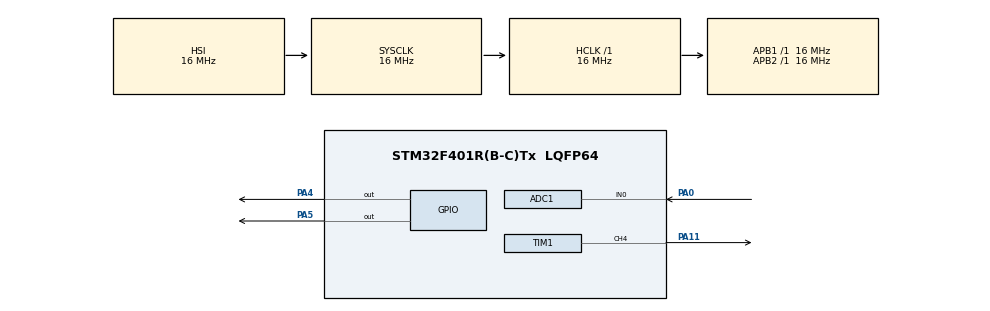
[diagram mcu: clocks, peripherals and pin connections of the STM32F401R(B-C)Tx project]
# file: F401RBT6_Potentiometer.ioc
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ADC1.Channel-2\#ChannelRegularConversion=ADC_CHANNEL_0
ADC1.NbrOfConversionFlag=1
ADC1.Rank-2\#ChannelRegularConversion=1
ADC1.SamplingTime-2\#ChannelRegularConversion=ADC_SAMPLETIME_15CYCLES
ADC1.master=1
Mcu.Family=STM32F4
Mcu.Name=STM32F401R(B-C)Tx
Mcu.Package=LQFP64
NVIC.PriorityGroup=NVIC_PRIORITYGROUP_4
PA0-WKUP.Signal=ADCx_IN0
PA11.Signal=S_TIM1_CH4
PA13.Mode=Serial_Wire
PA13.Signal=SYS_JTMS-SWDIO
PA14.Mode=Serial_Wire
PA14.Signal=SYS_JTCK-SWCLK
PA4.Signal=GPIO_Output
PA5.Signal=GPIO_Output
PC14-OSC32_IN.Mode=LSE-External-Oscillator
PC14-OSC32_IN.Signal=RCC_OSC32_IN
PC15-OSC32_OUT.Mode=LSE-External-Oscillator
PC15-OSC32_OUT.Signal=RCC_OSC32_OUT
PH0\ -\ OSC_IN.Mode=HSE-External-Oscillator
PH0\ -\ OSC_IN.Signal=RCC_OSC_IN
PH1\ -\ OSC_OUT.Mode=HSE-External-Oscillator
PH1\ -\ OSC_OUT.Signal=RCC_OSC_OUT
ProjectManager.HeapSize=0x200
ProjectManager.StackSize=0x400
ProjectManager.TargetToolchain=STM32CubeIDE
RCC.AHBFreq_Value=16000000
RCC.APB1Freq_Value=16000000
RCC.APB2Freq_Value=16000000
RCC.CortexFreq_Value=16000000
RCC.HSE_VALUE=25000000
RCC.HSI_VALUE=16000000
RCC.SYSCLKFreq_VALUE=16000000
RCC.VCOOutputFreq_Value=192000000
SH.ADCx_IN0.0=ADC1_IN0,IN0
SH.S_TIM1_CH4.0=TIM1_CH4,PWM Generation4 CH4
TIM1.AutoReloadPreload=TIM_AUTORELOAD_PRELOAD_ENABLE
TIM1.Channel-PWM\ Generation4\ CH4=TIM_CHANNEL_4
TIM1.Period=999
TIM1.Prescaler=79
board=custom

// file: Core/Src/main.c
/* USER CODE BEGIN Header */
/**
 ******************************************************************************
 * @file           : main.c
 * @brief          : Main program body
 ******************************************************************************
 * @attention
 *
 * Copyright (c) 2025 STMicroelectronics.
 * All rights reserved.
 *
 * This software is licensed under terms that can be found in the LICENSE file
 * in the root directory of this software component.
 * If no LICENSE file comes with this software, it is provided AS-IS.
 *
 ******************************************************************************
 */
/* USER CODE END Header */
#include "main.h"

ADC_HandleTypeDef hadc1;

TIM_HandleTypeDef htim1;

void SystemClock_Config(void);
static void MX_GPIO_Init(void);
static void MX_ADC1_Init(void);
static void MX_TIM1_Init(void);
/* USER CODE BEGIN PFP */
uint32_t adcValue;
uint32_t pwmValue;
/* USER CODE END PFP */

int main(void) {

	/* MCU Configuration--------------------------------------------------------*/

	/* Reset of all peripherals, Initializes the Flash interface and the Systick. */
	HAL_Init();

	/* Configure the system clock */
	SystemClock_Config();

	/* Initialize all configured peripherals */
	MX_GPIO_Init();
	MX_ADC1_Init();
	MX_TIM1_Init();
	/* USER CODE BEGIN 2 */
	HAL_TIM_PWM_Start(&htim1, TIM_CHANNEL_4);
	/* USER CODE END 2 */
	HAL_GPIO_WritePin(GPIOA, GPIO_PIN_4, GPIO_PIN_SET);   // IN1 = HIGH
	HAL_GPIO_WritePin(GPIOA, GPIO_PIN_5, GPIO_PIN_RESET); // IN2 = LOW
	/* Infinite loop */
	while (1) {
		HAL_ADC_Start(&hadc1);
		HAL_ADC_PollForConversion(&hadc1, HAL_MAX_DELAY);
		adcValue = HAL_ADC_GetValue(&hadc1); // 12-bit: 0–4095

		// Map 0–4095 to 0–999 (PWM duty)
		pwmValue = (adcValue * 999) / 4095;

		// Update PWM duty cycle
		__HAL_TIM_SET_COMPARE(&htim1, TIM_CHANNEL_4, pwmValue);

		HAL_Delay(10);
	}
}

void SystemClock_Config(void) {
	RCC_OscInitTypeDef RCC_OscInitStruct = { 0 };
	RCC_ClkInitTypeDef RCC_ClkInitStruct = { 0 };

	/** Configure the main internal regulator output voltage
	 */
	__HAL_RCC_PWR_CLK_ENABLE();
	__HAL_PWR_VOLTAGESCALING_CONFIG(PWR_REGULATOR_VOLTAGE_SCALE2);

	/** Initializes the RCC Oscillators according to the specified parameters
	 * in the RCC_OscInitTypeDef structure.
	 */
	RCC_OscInitStruct.OscillatorType = RCC_OSCILLATORTYPE_HSI;
	RCC_OscInitStruct.HSIState = RCC_HSI_ON;
	RCC_OscInitStruct.HSICalibrationValue = RCC_HSICALIBRATION_DEFAULT;
	RCC_OscInitStruct.PLL.PLLState = RCC_PLL_NONE;
	if (HAL_RCC_OscConfig(&RCC_OscInitStruct) != HAL_OK) {
		Error_Handler();
	}

	/** Initializes the CPU, AHB and APB buses clocks
	 */
	RCC_ClkInitStruct.ClockType = RCC_CLOCKTYPE_HCLK | RCC_CLOCKTYPE_SYSCLK
			| RCC_CLOCKTYPE_PCLK1 | RCC_CLOCKTYPE_PCLK2;
	RCC_ClkInitStruct.SYSCLKSource = RCC_SYSCLKSOURCE_HSI;
	RCC_ClkInitStruct.AHBCLKDivider = RCC_SYSCLK_DIV1;
	RCC_ClkInitStruct.APB1CLKDivider = RCC_HCLK_DIV1;
	RCC_ClkInitStruct.APB2CLKDivider = RCC_HCLK_DIV1;

	if (HAL_RCC_ClockConfig(&RCC_ClkInitStruct, FLASH_LATENCY_0) != HAL_OK) {
		Error_Handler();
	}
}

static void MX_ADC1_Init(void) {

	ADC_ChannelConfTypeDef sConfig = { 0 };

	/** Configure the global features of the ADC (Clock, Resolution, Data Alignment and number of conversion)
	 */
	hadc1.Instance = ADC1;
	hadc1.Init.ClockPrescaler = ADC_CLOCK_SYNC_PCLK_DIV2;
	hadc1.Init.Resolution = ADC_RESOLUTION_12B;
	hadc1.Init.ScanConvMode = DISABLE;
	hadc1.Init.ContinuousConvMode = DISABLE;
	hadc1.Init.DiscontinuousConvMode = DISABLE;
	hadc1.Init.ExternalTrigConvEdge = ADC_EXTERNALTRIGCONVEDGE_NONE;
	hadc1.Init.ExternalTrigConv = ADC_SOFTWARE_START;
	hadc1.Init.DataAlign = ADC_DATAALIGN_RIGHT;
	hadc1.Init.NbrOfConversion = 1;
	hadc1.Init.DMAContinuousRequests = DISABLE;
	hadc1.Init.EOCSelection = ADC_EOC_SINGLE_CONV;
	if (HAL_ADC_Init(&hadc1) != HAL_OK) {
		Error_Handler();
	}

	/** Configure for the selected ADC regular channel its corresponding rank in the sequencer and its sample time.
	 */
	sConfig.Channel = ADC_CHANNEL_0;
	sConfig.Rank = 1;
	sConfig.SamplingTime = ADC_SAMPLETIME_15CYCLES;
	if (HAL_ADC_ConfigChannel(&hadc1, &sConfig) != HAL_OK) {
		Error_Handler();
	}

}

static void MX_TIM1_Init(void) {

	TIM_MasterConfigTypeDef sMasterConfig = { 0 };
	TIM_OC_InitTypeDef sConfigOC = { 0 };
	TIM_BreakDeadTimeConfigTypeDef sBreakDeadTimeConfig = { 0 };

	htim1.Instance = TIM1;
	htim1.Init.Prescaler = 79;
	htim1.Init.CounterMode = TIM_COUNTERMODE_UP;
	htim1.Init.Period = 999;
	htim1.Init.ClockDivision = TIM_CLOCKDIVISION_DIV1;
	htim1.Init.RepetitionCounter = 0;
	htim1.Init.AutoReloadPreload = TIM_AUTORELOAD_PRELOAD_ENABLE;
	if (HAL_TIM_PWM_Init(&htim1) != HAL_OK) {
		Error_Handler();
	}
	sMasterConfig.MasterOutputTrigger = TIM_TRGO_RESET;
	sMasterConfig.MasterSlaveMode = TIM_MASTERSLAVEMODE_DISABLE;
	if (HAL_TIMEx_MasterConfigSynchronization(&htim1, &sMasterConfig)
			!= HAL_OK) {
		Error_Handler();
	}
	sConfigOC.OCMode = TIM_OCMODE_PWM1;
	sConfigOC.Pulse = 0;
	sConfigOC.OCPolarity = TIM_OCPOLARITY_HIGH;
	sConfigOC.OCFastMode = TIM_OCFAST_DISABLE;
	sConfigOC.OCIdleState = TIM_OCIDLESTATE_RESET;
	sConfigOC.OCNIdleState = TIM_OCNIDLESTATE_RESET;
	if (HAL_TIM_PWM_ConfigChannel(&htim1, &sConfigOC, TIM_CHANNEL_4)
			!= HAL_OK) {
		Error_Handler();
	}
	sBreakDeadTimeConfig.OffStateRunMode = TIM_OSSR_DISABLE;
	sBreakDeadTimeConfig.OffStateIDLEMode = TIM_OSSI_DISABLE;
	sBreakDeadTimeConfig.LockLevel = TIM_LOCKLEVEL_OFF;
	sBreakDeadTimeConfig.DeadTime = 0;
	sBreakDeadTimeConfig.BreakState = TIM_BREAK_DISABLE;
	sBreakDeadTimeConfig.BreakPolarity = TIM_BREAKPOLARITY_HIGH;
	sBreakDeadTimeConfig.AutomaticOutput = TIM_AUTOMATICOUTPUT_DISABLE;
	if (HAL_TIMEx_ConfigBreakDeadTime(&htim1, &sBreakDeadTimeConfig)
			!= HAL_OK) {
		Error_Handler();
	}
	HAL_TIM_MspPostInit(&htim1);

}

static void MX_GPIO_Init(void) {
	GPIO_InitTypeDef GPIO_InitStruct = { 0 };

	/* GPIO Ports Clock Enable */
	__HAL_RCC_GPIOC_CLK_ENABLE();
	__HAL_RCC_GPIOH_CLK_ENABLE();
	__HAL_RCC_GPIOA_CLK_ENABLE();

	/*Configure GPIO pin Output Level */
	HAL_GPIO_WritePin(GPIOA, GPIO_PIN_4 | GPIO_PIN_5, GPIO_PIN_RESET);

	/*Configure GPIO pins : PA4 PA5 */
	GPIO_InitStruct.Pin = GPIO_PIN_4 | GPIO_PIN_5;
	GPIO_InitStruct.Mode = GPIO_MODE_OUTPUT_PP;
	GPIO_InitStruct.Pull = GPIO_NOPULL;
	GPIO_InitStruct.Speed = GPIO_SPEED_FREQ_LOW;
	HAL_GPIO_Init(GPIOA, &GPIO_InitStruct);

}

void Error_Handler(void) {
	__disable_irq();
	while (1) {
	}
}
